/*
 * The MIT License (MIT)
 *
 * Copyright (c) 2015-2019 Erik Moqvist
 *
 * Permission is hereby granted, free of charge, to any person obtaining a copy
 * of this software and associated documentation files (the "Software"), to deal
 * in the Software without restriction, including without limitation the rights
 * to use, copy, modify, merge, publish, distribute, sublicense, and/or sell
 * copies of the Software, and to permit persons to whom the Software is
 * furnished to do so, subject to the following conditions:
 *
 * The above copyright notice and this permission notice shall be included in all
 * copies or substantial portions of the Software.
 *
 * THE SOFTWARE IS PROVIDED "AS IS", WITHOUT WARRANTY OF ANY KIND, EXPRESS OR
 * IMPLIED, INCLUDING BUT NOT LIMITED TO THE WARRANTIES OF MERCHANTABILITY,
 * FITNESS FOR A PARTICULAR PURPOSE AND NONINFRINGEMENT. IN NO EVENT SHALL THE
 * AUTHORS OR COPYRIGHT HOLDERS BE LIABLE FOR ANY CLAIM, DAMAGES OR OTHER
 * LIABILITY, WHETHER IN AN ACTION OF CONTRACT, TORT OR OTHERWISE, ARISING FROM,
 * OUT OF OR IN CONNECTION WITH THE SOFTWARE OR THE USE OR OTHER DEALINGS IN THE
 * SOFTWARE.
 */

VERSION "VER"

NS_ :

BS_:

BU_: E1

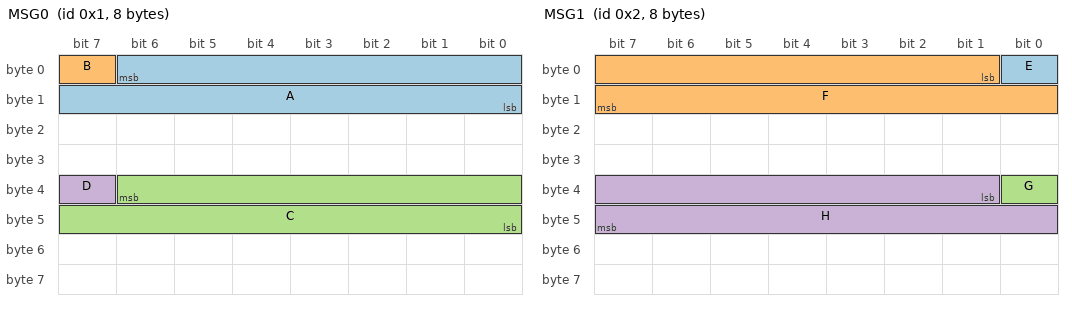
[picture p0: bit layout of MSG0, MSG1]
BO_ 1 MSG0: 8 E1
 SG_ A : 6|15@0+ (1,0) [0|32767] ""  E1
 SG_ B : 7|1@0+ (1,0) [0|1] ""  E1
 SG_ C : 38|15@0+ (1,0) [0|32767] ""  E1
 SG_ D : 39|1@0+ (1,0) [0|1] ""  E1

BO_ 2 MSG1: 8 E1
 SG_ E : 0|1@1+ (1,0) [0|1] ""  E1
 SG_ F : 1|15@1+ (1,0) [0|32767] ""  E1
 SG_ G : 32|1@1+ (1,0) [0|1] ""  E1
 SG_ H : 33|15@1+ (1,0) [0|32767] ""  E1

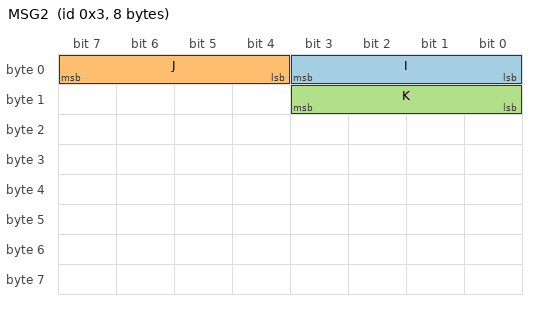
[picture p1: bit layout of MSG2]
BO_ 3 MSG2: 8 E1
 SG_ I : 0|4@1+ (1,0) [0|15] ""  E1
 SG_ J : 4|4@1+ (1,0) [0|15] ""  E1
 SG_ K : 8|4@1+ (1,0) [0|15] ""  E1

BO_ 4 MSG3: 8 E1
 SG_ L : 7|64@0+ (1,0) [0|18446744073709551615] ""  E1

BO_ 5 MSG4: 8 E1
 SG_ M : 0|64@1+ (1,0) [0|18446744073709551615] ""  E1
